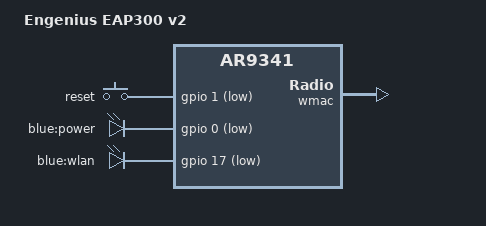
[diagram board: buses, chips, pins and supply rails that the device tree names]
// SPDX-License-Identifier: GPL-2.0-or-later OR MIT

#include "ar9341.dtsi"
#include "ar934x_senao_loader.dtsi"

#include <dt-bindings/gpio/gpio.h>
#include <dt-bindings/input/input.h>

/ {
	model = "Engenius EAP300 v2";
	compatible = "engenius,eap300-v2", "qca,ar9341";

	aliases {
		led-boot = &led_power;
		led-failsafe = &led_power;
		led-running = &led_power;
		led-upgrade = &led_power;
	};

	keys {
		compatible = "gpio-keys";

		reset {
			label = "reset";
			gpios = <&gpio 1 GPIO_ACTIVE_LOW>;
			debounce-interval = <60>;
			linux,code = <KEY_RESTART>;
		};
	};

	leds {
		compatible = "gpio-leds";

		led_power: power {
			label = "blue:power";
			gpios = <&gpio 0 GPIO_ACTIVE_LOW>;
			default-state = "on";
		};

		wlan {
			label = "blue:wlan";
			gpios = <&gpio 17 GPIO_ACTIVE_LOW>;
			linux,default-trigger = "phy0tpt";
		};
	};
};

&eth1 {
	mtd-mac-address = <&art 0x0>;
};

&wmac {
	status = "okay";

	mtd-cal-data = <&art 0x1000>;
};
